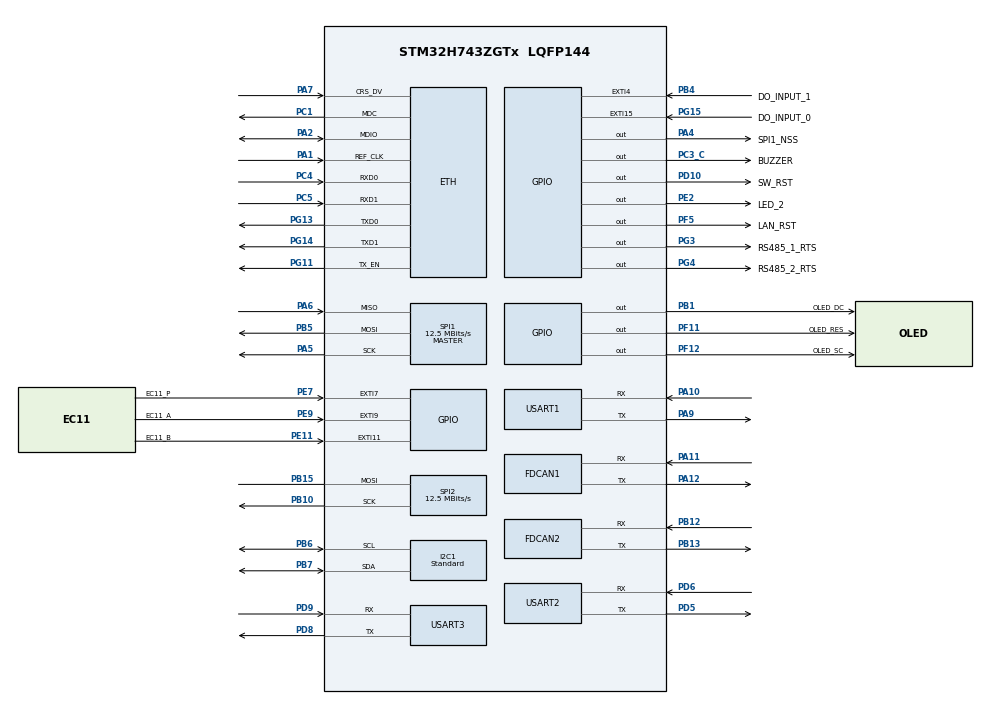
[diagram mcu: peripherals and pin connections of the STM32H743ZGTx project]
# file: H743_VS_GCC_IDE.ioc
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CORTEX_M7.AccessPermission_S-Cortex_Memory_Protection_Unit_Region1_Settings_S=MPU_REGION_FULL_ACCESS
CORTEX_M7.AccessPermission_S-Cortex_Memory_Protection_Unit_Region2_Settings_S=MPU_REGION_FULL_ACCESS
CORTEX_M7.AccessPermission_S-Cortex_Memory_Protection_Unit_Region3_Settings_S=MPU_REGION_FULL_ACCESS
CORTEX_M7.AccessPermission_S-Cortex_Memory_Protection_Unit_Region4_Settings_S=MPU_REGION_FULL_ACCESS
CORTEX_M7.AccessPermission_Spec=MPU_REGION_FULL_ACCESS
CORTEX_M7.BaseAddress_S-Cortex_Memory_Protection_Unit_Region1_Settings_S=0x30000000
CORTEX_M7.BaseAddress_S-Cortex_Memory_Protection_Unit_Region2_Settings_S=0x30004000
CORTEX_M7.BaseAddress_S-Cortex_Memory_Protection_Unit_Region3_Settings_S=0x38000000
CORTEX_M7.BaseAddress_S-Cortex_Memory_Protection_Unit_Region4_Settings_S=0x38800000
CORTEX_M7.BaseAddress_Spec=0x24000000
CORTEX_M7.CPU_DCache=Enabled
CORTEX_M7.CPU_ICache=Enabled
CORTEX_M7.DisableExec_S-Cortex_Memory_Protection_Unit_Region1_Settings_S=MPU_INSTRUCTION_ACCESS_DISABLE
CORTEX_M7.DisableExec_S-Cortex_Memory_Protection_Unit_Region2_Settings_S=MPU_INSTRUCTION_ACCESS_DISABLE
CORTEX_M7.DisableExec_S-Cortex_Memory_Protection_Unit_Region3_Settings_S=MPU_INSTRUCTION_ACCESS_DISABLE
CORTEX_M7.DisableExec_S-Cortex_Memory_Protection_Unit_Region4_Settings_S=MPU_INSTRUCTION_ACCESS_DISABLE
CORTEX_M7.DisableExec_Spec=MPU_INSTRUCTION_ACCESS_DISABLE
CORTEX_M7.Enable_S-Cortex_Memory_Protection_Unit_Region1_Settings_S=MPU_REGION_ENABLE
CORTEX_M7.Enable_S-Cortex_Memory_Protection_Unit_Region2_Settings_S=MPU_REGION_ENABLE
CORTEX_M7.Enable_S-Cortex_Memory_Protection_Unit_Region3_Settings_S=MPU_REGION_ENABLE
CORTEX_M7.Enable_S-Cortex_Memory_Protection_Unit_Region4_Settings_S=MPU_REGION_ENABLE
CORTEX_M7.Enable_S-Cortex_Memory_Protection_Unit_Region5_Settings_S=__NULL
CORTEX_M7.IsBufferable_S-Cortex_Memory_Protection_Unit_Region1_Settings_S=MPU_ACCESS_BUFFERABLE
CORTEX_M7.IsBufferable_S-Cortex_Memory_Protection_Unit_Region2_Settings_S=MPU_ACCESS_BUFFERABLE
CORTEX_M7.IsBufferable_S-Cortex_Memory_Protection_Unit_Region3_Settings_S=MPU_ACCESS_BUFFERABLE
CORTEX_M7.IsBufferable_S-Cortex_Memory_Protection_Unit_Region4_Settings_S=MPU_ACCESS_NOT_BUFFERABLE
CORTEX_M7.IsBufferable_Spec=MPU_ACCESS_NOT_BUFFERABLE
CORTEX_M7.IsCacheable_S-Cortex_Memory_Protection_Unit_Region2_Settings_S=MPU_ACCESS_NOT_CACHEABLE
CORTEX_M7.IsCacheable_S-Cortex_Memory_Protection_Unit_Region4_Settings_S=MPU_ACCESS_NOT_CACHEABLE
CORTEX_M7.IsCacheable_Spec=MPU_ACCESS_CACHEABLE
CORTEX_M7.IsShareable_S-Cortex_Memory_Protection_Unit_Region1_Settings_S=MPU_ACCESS_SHAREABLE
CORTEX_M7.IsShareable_S-Cortex_Memory_Protection_Unit_Region2_Settings_S=MPU_ACCESS_SHAREABLE
CORTEX_M7.IsShareable_S-Cortex_Memory_Protection_Unit_Region3_Settings_S=MPU_ACCESS_SHAREABLE
CORTEX_M7.IsShareable_S-Cortex_Memory_Protection_Unit_Region4_Settings_S=MPU_ACCESS_NOT_SHAREABLE
CORTEX_M7.IsShareable_Spec=MPU_ACCESS_NOT_SHAREABLE
CORTEX_M7.Size_S-Cortex_Memory_Protection_Unit_Region1_Settings_S=MPU_REGION_SIZE_256KB
CORTEX_M7.Size_S-Cortex_Memory_Protection_Unit_Region2_Settings_S=MPU_REGION_SIZE_32KB
CORTEX_M7.Size_S-Cortex_Memory_Protection_Unit_Region3_Settings_S=MPU_REGION_SIZE_64KB
CORTEX_M7.Size_S-Cortex_Memory_Protection_Unit_Region4_Settings_S=MPU_REGION_SIZE_4KB
CORTEX_M7.Size_Spec=MPU_REGION_SIZE_512KB
CORTEX_M7.SubRegionDisable_Spec=0x00
CORTEX_M7.TypeExtField_S-Cortex_Memory_Protection_Unit_Region2_Settings_S=MPU_TEX_LEVEL0
CORTEX_M7.default_mode_Activation=1
Dma.I2C1_TX.0.Direction=DMA_MEMORY_TO_PERIPH
Dma.I2C1_TX.0.EventEnable=DISABLE
Dma.I2C1_TX.0.FIFOMode=DMA_FIFOMODE_DISABLE
Dma.I2C1_TX.0.Instance=DMA1_Stream3
Dma.I2C1_TX.0.MemDataAlignment=DMA_MDATAALIGN_BYTE
Dma.I2C1_TX.0.MemInc=DMA_MINC_ENABLE
Dma.I2C1_TX.0.Mode=DMA_NORMAL
Dma.I2C1_TX.0.PeriphDataAlignment=DMA_PDATAALIGN_BYTE
Dma.I2C1_TX.0.PeriphInc=DMA_PINC_DISABLE
Dma.I2C1_TX.0.Polarity=HAL_DMAMUX_REQ_GEN_RISING
Dma.I2C1_TX.0.Priority=DMA_PRIORITY_LOW
Dma.I2C1_TX.0.RequestNumber=1
Dma.I2C1_TX.0.SignalID=NONE
Dma.I2C1_TX.0.SyncEnable=DISABLE
Dma.I2C1_TX.0.SyncPolarity=HAL_DMAMUX_SYNC_NO_EVENT
Dma.I2C1_TX.0.SyncRequestNumber=1
Dma.I2C1_TX.0.SyncSignalID=NONE
Dma.Request0=I2C1_TX
Dma.Request1=USART2_RX
Dma.Request2=USART2_TX
Dma.Request3=USART1_RX
Dma.Request4=USART1_TX
Dma.USART1_RX.3.Direction=DMA_PERIPH_TO_MEMORY
Dma.USART1_RX.3.EventEnable=DISABLE
Dma.USART1_RX.3.FIFOMode=DMA_FIFOMODE_DISABLE
Dma.USART1_RX.3.Instance=DMA1_Stream0
Dma.USART1_RX.3.MemDataAlignment=DMA_MDATAALIGN_BYTE
Dma.USART1_RX.3.MemInc=DMA_MINC_ENABLE
Dma.USART1_RX.3.Mode=DMA_NORMAL
Dma.USART1_RX.3.PeriphDataAlignment=DMA_PDATAALIGN_BYTE
Dma.USART1_RX.3.PeriphInc=DMA_PINC_DISABLE
Dma.USART1_RX.3.Polarity=HAL_DMAMUX_REQ_GEN_RISING
Dma.USART1_RX.3.Priority=DMA_PRIORITY_HIGH
Dma.USART1_RX.3.RequestNumber=1
Dma.USART1_RX.3.SignalID=NONE
Dma.USART1_RX.3.SyncEnable=DISABLE
Dma.USART1_RX.3.SyncPolarity=HAL_DMAMUX_SYNC_NO_EVENT
Dma.USART1_RX.3.SyncRequestNumber=1
Dma.USART1_RX.3.SyncSignalID=NONE
Dma.USART1_TX.4.Direction=DMA_MEMORY_TO_PERIPH
Dma.USART1_TX.4.EventEnable=DISABLE
Dma.USART1_TX.4.FIFOMode=DMA_FIFOMODE_DISABLE
Dma.USART1_TX.4.Instance=DMA1_Stream1
Dma.USART1_TX.4.MemDataAlignment=DMA_MDATAALIGN_BYTE
Dma.USART1_TX.4.MemInc=DMA_MINC_ENABLE
Dma.USART1_TX.4.Mode=DMA_NORMAL
Dma.USART1_TX.4.PeriphDataAlignment=DMA_PDATAALIGN_BYTE
Dma.USART1_TX.4.PeriphInc=DMA_PINC_DISABLE
Dma.USART1_TX.4.Polarity=HAL_DMAMUX_REQ_GEN_RISING
Dma.USART1_TX.4.Priority=DMA_PRIORITY_HIGH
Dma.USART1_TX.4.RequestNumber=1
Dma.USART1_TX.4.SignalID=NONE
Dma.USART1_TX.4.SyncEnable=DISABLE
Dma.USART1_TX.4.SyncPolarity=HAL_DMAMUX_SYNC_NO_EVENT
Dma.USART1_TX.4.SyncRequestNumber=1
Dma.USART1_TX.4.SyncSignalID=NONE
Dma.USART2_RX.1.Direction=DMA_PERIPH_TO_MEMORY
Dma.USART2_RX.1.EventEnable=DISABLE
Dma.USART2_RX.1.FIFOMode=DMA_FIFOMODE_DISABLE
Dma.USART2_RX.1.Instance=DMA1_Stream4
Dma.USART2_RX.1.MemDataAlignment=DMA_MDATAALIGN_BYTE
Dma.USART2_RX.1.MemInc=DMA_MINC_ENABLE
Dma.USART2_RX.1.Mode=DMA_NORMAL
Dma.USART2_RX.1.PeriphDataAlignment=DMA_PDATAALIGN_BYTE
Dma.USART2_RX.1.PeriphInc=DMA_PINC_DISABLE
Dma.USART2_RX.1.Polarity=HAL_DMAMUX_REQ_GEN_RISING
Dma.USART2_RX.1.Priority=DMA_PRIORITY_LOW
Dma.USART2_RX.1.RequestNumber=1
Dma.USART2_RX.1.SignalID=NONE
Dma.USART2_RX.1.SyncEnable=DISABLE
Dma.USART2_RX.1.SyncPolarity=HAL_DMAMUX_SYNC_NO_EVENT
Dma.USART2_RX.1.SyncRequestNumber=1
Dma.USART2_RX.1.SyncSignalID=NONE
Dma.USART2_TX.2.Direction=DMA_MEMORY_TO_PERIPH
Dma.USART2_TX.2.EventEnable=DISABLE
Dma.USART2_TX.2.FIFOMode=DMA_FIFOMODE_DISABLE
Dma.USART2_TX.2.Instance=DMA1_Stream5
Dma.USART2_TX.2.MemDataAlignment=DMA_MDATAALIGN_BYTE
Dma.USART2_TX.2.MemInc=DMA_MINC_ENABLE
Dma.USART2_TX.2.Mode=DMA_NORMAL
Dma.USART2_TX.2.PeriphDataAlignment=DMA_PDATAALIGN_BYTE
Dma.USART2_TX.2.PeriphInc=DMA_PINC_DISABLE
Dma.USART2_TX.2.Polarity=HAL_DMAMUX_REQ_GEN_RISING
Dma.USART2_TX.2.Priority=DMA_PRIORITY_LOW
Dma.USART2_TX.2.RequestNumber=1
Dma.USART2_TX.2.SignalID=NONE
Dma.USART2_TX.2.SyncEnable=DISABLE
Dma.USART2_TX.2.SyncPolarity=HAL_DMAMUX_SYNC_NO_EVENT
Dma.USART2_TX.2.SyncRequestNumber=1
Dma.USART2_TX.2.SyncSignalID=NONE
ETH.ETH_RX_DESC_CNT=4
ETH.ETH_TX_DESC_CNT=4
ETH.MediaInterface=HAL_ETH_RMII_MODE
ETH.RxBuffLen=1536
ETH.RxBufferAddress=0x30000200
ETH.RxDescAddress=0x30000000
ETH.TxDescAddress=0x30000100
FDCAN1.CalculateBaudRateNominal=500000
FDCAN1.CalculateTimeBitNominal=2000
FDCAN1.CalculateTimeQuantumNominal=50.0
FDCAN1.DataPrescaler=5
FDCAN1.DataTimeSeg1=31
FDCAN1.DataTimeSeg2=8
FDCAN1.NominalPrescaler=5
FDCAN1.NominalTimeSeg1=31
FDCAN1.NominalTimeSeg2=8
FDCAN1.RxFifo0ElmtsNbr=32
FDCAN1.StdFiltersNbr=1
FDCAN1.TxFifoQueueElmtsNbr=16
FDCAN2.CalculateBaudRateNominal=500000
FDCAN2.CalculateTimeBitNominal=2000
FDCAN2.CalculateTimeQuantumNominal=50.0
FDCAN2.DataPrescaler=5
FDCAN2.DataTimeSeg1=31
FDCAN2.DataTimeSeg2=8
FDCAN2.MessageRAMOffset=0x406
FDCAN2.NominalPrescaler=5
FDCAN2.NominalTimeSeg1=31
FDCAN2.NominalTimeSeg2=8
FDCAN2.RxFifo1ElmtsNbr=32
FDCAN2.StdFiltersNbr=1
FDCAN2.TxFifoQueueElmtsNbr=32
FREERTOS.HEAP_NUMBER=4
FREERTOS.Tasks01=defaultTask,24,4096,StartDefaultTask,Default,NULL,Dynamic,NULL,NULL
FREERTOS.configENABLE_FPU=1
FREERTOS.configMINIMAL_STACK_SIZE=1024
FREERTOS.configTIMER_QUEUE_LENGTH=20
FREERTOS.configTIMER_TASK_PRIORITY=24
FREERTOS.configTIMER_TASK_STACK_DEPTH=20480
FREERTOS.configTOTAL_HEAP_SIZE=200*1024
FREERTOS.configUSE_NEWLIB_REENTRANT=1
FREERTOS.configUSE_TICKLESS_IDLE=1
I2C1.CustomTiming=Disabled
I2C1.I2C_Coeff_DF=10
I2C1.I2C_Fall_Time=20
I2C1.I2C_Rise_Time=20
I2C1.I2C_Speed_Mode=I2C_Standard
I2C1.Timing=0x10D0E0FF
IWDG1.Prescaler=IWDG_PRESCALER_4
LWIP.BSP.number=1
LWIP.DEFAULT_THREAD_PRIO=28
LWIP.ETH_RX_BUFFER_CNT=128
LWIP.IP_ADDRESS=000.000.000.000
LWIP.LWIP_ALLOW_MEM_FREE_FROM_OTHER_CONTEXT=1
LWIP.LWIP_DHCP=0
LWIP.LWIP_NETCONN_FULLDUPLEX=1
LWIP.LWIP_RAM_HEAP_POINTER=0x30000800
LWIP.LWIP_SNTP=1
LWIP.LWIP_TFTP=1
LWIP.MEMP_MEM_INIT=1
LWIP.MEMP_MEM_MALLOC=1
LWIP.MEMP_NUM_PBUF=64
LWIP.MEMP_USE_CUSTOM_POOLS=1
LWIP.MEM_LIBC_MALLOC=1
LWIP.MEM_SIZE=65535
LWIP.NETMASK_ADDRESS=000.000.000.000
LWIP.PBUF_POOL_SIZE=128
LWIP.SLIPIF_THREAD_PRIO=28
LWIP.TCPIP_THREAD_PRIO=32
LWIP.TCPIP_THREAD_STACKSIZE=4096
LWIP.TCP_SND_QUEUELEN=24
LWIP.Version=v2.1.2_Cube
LWIP0.BSP.STBoard=false
LWIP0.BSP.api=BSP_COMPONENT_DRIVER
LWIP0.BSP.component=LAN8742
LWIP0.BSP.instance=LAN8742
LWIP0.BSP.name=Driver_PHY
LWIP0.BSP.semaphore=S_LAN8742
LWIP0.BSP.solution=LAN8742
Mcu.Family=STM32H7
Mcu.Name=STM32H743ZGTx
Mcu.Package=LQFP144
NVIC.DMA1_Stream0_IRQn=true\:5\:0\:false\:false\:true\:true\:false\:true\:true
NVIC.DMA1_Stream1_IRQn=true\:5\:0\:false\:false\:true\:true\:false\:true\:true
NVIC.DMA1_Stream3_IRQn=true\:5\:0\:false\:false\:true\:true\:false\:true\:true
NVIC.DMA1_Stream4_IRQn=true\:5\:0\:false\:false\:true\:true\:false\:true\:true
NVIC.DMA1_Stream5_IRQn=true\:5\:0\:false\:false\:true\:true\:false\:true\:true
NVIC.ETH_IRQn=true\:5\:0\:true\:false\:true\:true\:true\:true\:true
NVIC.EXTI15_10_IRQn=true\:6\:0\:true\:false\:true\:true\:true\:true\:true
NVIC.EXTI4_IRQn=true\:6\:0\:true\:false\:true\:true\:true\:true\:true
NVIC.EXTI9_5_IRQn=true\:6\:0\:true\:false\:true\:false\:true\:true\:true
NVIC.FDCAN1_IT0_IRQn=true\:5\:0\:false\:false\:true\:true\:true\:true\:true
NVIC.FDCAN2_IT0_IRQn=true\:5\:0\:false\:false\:true\:true\:true\:true\:true
NVIC.PriorityGroup=NVIC_PRIORITYGROUP_4
NVIC.TIM2_IRQn=true\:5\:0\:false\:false\:false\:true\:true\:true\:true
NVIC.TIM7_IRQn=true\:15\:0\:false\:false\:true\:false\:false\:true\:true
NVIC.TimeBase=TIM7_IRQn
NVIC.TimeBaseIP=TIM7
NVIC.USART1_IRQn=true\:7\:0\:true\:false\:false\:true\:true\:true\:true
NVIC.USART2_IRQn=true\:5\:0\:true\:false\:true\:true\:true\:true\:true
NVIC.USART3_IRQn=true\:5\:0\:true\:false\:false\:true\:true\:true\:true
PA1.GPIO_Mode=GPIO_MODE_AF_PP
PA1.GPIO_PuPd=GPIO_NOPULL
PA1.GPIO_Speed=GPIO_SPEED_FREQ_VERY_HIGH
PA1.Mode=RMII
PA1.Signal=ETH_REF_CLK
PA10.GPIO_PuPd=GPIO_PULLUP
PA10.GPIO_Speed=GPIO_SPEED_FREQ_HIGH
PA10.Mode=Asynchronous
PA10.Signal=USART1_RX
PA11.Mode=FDCAN_Activate
PA11.Signal=FDCAN1_RX
PA12.Mode=FDCAN_Activate
PA12.Signal=FDCAN1_TX
PA13\ (JTMS/SWDIO).Mode=Serial_Wire
PA13\ (JTMS/SWDIO).Signal=DEBUG_JTMS-SWDIO
PA14\ (JTCK/SWCLK).Mode=Serial_Wire
PA14\ (JTCK/SWCLK).Signal=DEBUG_JTCK-SWCLK
PA2.GPIO_Mode=GPIO_MODE_AF_PP
PA2.GPIO_PuPd=GPIO_NOPULL
PA2.GPIO_Speed=GPIO_SPEED_FREQ_VERY_HIGH
PA2.Mode=RMII
PA2.Signal=ETH_MDIO
PA4.GPIO_Label=SPI1_NSS
PA4.GPIO_Speed=GPIO_SPEED_FREQ_MEDIUM
PA4.Signal=GPIO_Output
PA5.GPIO_Speed=GPIO_SPEED_FREQ_VERY_HIGH
PA5.Mode=Full_Duplex_Master
PA5.Signal=SPI1_SCK
PA6.GPIO_Speed=GPIO_SPEED_FREQ_VERY_HIGH
PA6.Mode=Full_Duplex_Master
PA6.Signal=SPI1_MISO
PA7.GPIO_Mode=GPIO_MODE_AF_PP
PA7.GPIO_PuPd=GPIO_NOPULL
PA7.GPIO_Speed=GPIO_SPEED_FREQ_VERY_HIGH
PA7.Mode=RMII
PA7.Signal=ETH_CRS_DV
PA9.GPIO_PuPd=GPIO_PULLUP
PA9.GPIO_Speed=GPIO_SPEED_FREQ_HIGH
PA9.Mode=Asynchronous
PA9.Signal=USART1_TX
PB1.GPIO_Label=OLED_DC
PB1.Signal=GPIO_Output
PB10.Mode=Simplex_Bidirectional_Master
PB10.Signal=SPI2_SCK
PB12.Mode=FDCAN_Activate
PB12.Signal=FDCAN2_RX
PB13.Mode=FDCAN_Activate
PB13.Signal=FDCAN2_TX
PB15.Mode=Simplex_Bidirectional_Master
PB15.Signal=SPI2_MOSI
PB4\ (NJTRST).GPIO_Label=DO_INPUT_1
PB4\ (NJTRST).Signal=GPXTI4
PB5.GPIO_Speed=GPIO_SPEED_FREQ_VERY_HIGH
PB5.Mode=Full_Duplex_Master
PB5.Signal=SPI1_MOSI
PB6.GPIO_Pu=GPIO_PULLUP
PB6.GPIO_Speed=GPIO_SPEED_FREQ_HIGH
PB6.Mode=I2C
PB6.Signal=I2C1_SCL
PB7.GPIO_Pu=GPIO_PULLUP
PB7.GPIO_Speed=GPIO_SPEED_FREQ_HIGH
PB7.Mode=I2C
PB7.Signal=I2C1_SDA
PC1.GPIO_Mode=GPIO_MODE_AF_PP
PC1.GPIO_PuPd=GPIO_NOPULL
PC1.GPIO_Speed=GPIO_SPEED_FREQ_VERY_HIGH
PC1.Mode=RMII
PC1.Signal=ETH_MDC
PC3_C.GPIO_Label=BUZZER
PC3_C.GPIO_Speed=GPIO_SPEED_FREQ_HIGH
PC3_C.Signal=GPIO_Output
PC4.GPIO_Mode=GPIO_MODE_AF_PP
PC4.GPIO_PuPd=GPIO_NOPULL
PC4.GPIO_Speed=GPIO_SPEED_FREQ_VERY_HIGH
PC4.Mode=RMII
PC4.Signal=ETH_RXD0
PC5.GPIO_Mode=GPIO_MODE_AF_PP
PC5.GPIO_PuPd=GPIO_NOPULL
PC5.GPIO_Speed=GPIO_SPEED_FREQ_VERY_HIGH
PC5.Mode=RMII
PC5.Signal=ETH_RXD1
PD10.GPIO_Label=SW_RST
PD10.Signal=GPIO_Output
PD5.GPIO_PuPd=GPIO_PULLUP
PD5.GPIO_Speed=GPIO_SPEED_FREQ_HIGH
PD5.Mode=Asynchronous
PD5.Signal=USART2_TX
PD6.GPIO_PuPd=GPIO_PULLUP
PD6.GPIO_Speed=GPIO_SPEED_FREQ_HIGH
PD6.Mode=Asynchronous
PD6.Signal=USART2_RX
PD8.GPIO_PuPd=GPIO_PULLUP
PD8.GPIO_Speed=GPIO_SPEED_FREQ_HIGH
PD8.Mode=Asynchronous
PD8.Signal=USART3_TX
PD9.GPIO_PuPd=GPIO_PULLUP
PD9.GPIO_Speed=GPIO_SPEED_FREQ_HIGH
PD9.Mode=Asynchronous
PD9.Signal=USART3_RX
PE11.GPIO_Label=EC11_B
PE11.Signal=GPXTI11
PE2.GPIO_Label=LED_2
PE2.GPIO_PuPd=GPIO_PULLUP
PE2.Signal=GPIO_Output
PE7.GPIO_Label=EC11_P
PE7.GPIO_ModeDefaultEXTI=GPIO_MODE_IT_RISING_FALLING
PE7.Signal=GPXTI7
PE9.GPIO_Label=EC11_A
PE9.Signal=GPXTI9
PF11.GPIO_Label=OLED_RES
PF11.Signal=GPIO_Output
PF12.GPIO_Label=OLED_SC
PF12.Signal=GPIO_Output
PF5.GPIO_Label=LAN_RST
PF5.GPIO_PuPd=GPIO_NOPULL
PF5.PinState=GPIO_PIN_SET
PF5.Signal=GPIO_Output
PG11.GPIO_Mode=GPIO_MODE_AF_PP
PG11.GPIO_PuPd=GPIO_NOPULL
PG11.GPIO_Speed=GPIO_SPEED_FREQ_VERY_HIGH
PG11.Mode=RMII
PG11.Signal=ETH_TX_EN
PG13.GPIO_Mode=GPIO_MODE_AF_PP
PG13.GPIO_PuPd=GPIO_NOPULL
PG13.GPIO_Speed=GPIO_SPEED_FREQ_VERY_HIGH
PG13.Mode=RMII
PG13.Signal=ETH_TXD0
PG14.GPIO_Mode=GPIO_MODE_AF_PP
PG14.GPIO_PuPd=GPIO_NOPULL
PG14.GPIO_Speed=GPIO_SPEED_FREQ_VERY_HIGH
PG14.Mode=RMII
PG14.Signal=ETH_TXD1
PG15.GPIO_Label=DO_INPUT_0
PG15.GPIO_PuPd=GPIO_PULLDOWN
PG15.Signal=GPXTI15
PG3.GPIO_Label=RS485_1_RTS
PG3.GPIO_ModeDefaultOutputPP=GPIO_MODE_OUTPUT_PP
PG3.GPIO_PuPd=GPIO_NOPULL
PG3.GPIO_Speed=GPIO_SPEED_FREQ_MEDIUM
PG3.PinState=GPIO_PIN_RESET
PG3.Signal=GPIO_Output
PG4.GPIO_Label=RS485_2_RTS
PG4.GPIO_PuPd=GPIO_NOPULL
PG4.GPIO_Speed=GPIO_SPEED_FREQ_MEDIUM
PG4.PinState=GPIO_PIN_RESET
PG4.Signal=GPIO_Output
PH0-OSC_IN\ (PH0).Mode=HSE-External-Oscillator
PH0-OSC_IN\ (PH0).Signal=RCC_OSC_IN
PH1-OSC_OUT\ (PH1).Mode=HSE-External-Oscillator
PH1-OSC_OUT\ (PH1).Signal=RCC_OSC_OUT
ProjectManager.HeapSize=0x1200
ProjectManager.StackSize=0x1000
ProjectManager.TargetToolchain=CMake
RCC.ADCFreq_Value=100000000
RCC.APB1Freq_Value=120000000
RCC.APB2Freq_Value=120000000
RCC.APB3Freq_Value=120000000
RCC.APB4Freq_Value=120000000
RCC.CortexFreq_Value=480000000
RCC.D1PPRE=RCC_APB3_DIV2
RCC.D2PPRE1=RCC_APB1_DIV2
RCC.D2PPRE2=RCC_APB2_DIV2
RCC.D3PPRE=RCC_APB4_DIV2
RCC.DIVM1=5
RCC.DIVM2=5
RCC.DIVM3=5
RCC.DIVN1=192
RCC.DIVN2=160
RCC.DIVN3=160
RCC.DIVP2=8
RCC.DIVP3=4
RCC.DIVQ2=8
RCC.DIVR3=8
RCC.FDCANCLockSelection=RCC_FDCANCLKSOURCE_PLL2
RCC.HCLKFreq_Value=240000000
RCC.HPRE=RCC_HCLK_DIV2
RCC.I2C123CLockSelection=RCC_I2C123CLKSOURCE_PLL3
RCC.PLLSourceVirtual=RCC_PLLSOURCE_HSE
RCC.SPI123CLockSelection=RCC_SPI123CLKSOURCE_PLL3
RCC.SYSCLKFreq_VALUE=480000000
RCC.SYSCLKSource=RCC_SYSCLKSOURCE_PLLCLK
RCC.USBFreq_Value=480000000
RTC.Format=RTC_FORMAT_BCD
RTC.Year=25
SPI1.BaudRatePrescaler=SPI_BAUDRATEPRESCALER_16
SPI1.CLKPhase=SPI_PHASE_1EDGE
SPI1.CLKPolarity=SPI_POLARITY_LOW
SPI1.CalculateBaudRate=12.5 MBits/s
SPI1.DataSize=SPI_DATASIZE_8BIT
SPI1.Direction=SPI_DIRECTION_2LINES
SPI1.FirstBit=SPI_FIRSTBIT_MSB
SPI1.Mode=SPI_MODE_MASTER
SPI1.VirtualType=VM_MASTER
SPI2.BaudRatePrescaler=SPI_BAUDRATEPRESCALER_16
SPI2.CLKPhase=SPI_PHASE_2EDGE
SPI2.CLKPolarity=SPI_POLARITY_HIGH
SPI2.CalculateBaudRate=12.5 MBits/s
SPI2.DataSize=SPI_DATASIZE_8BIT
SPI2.Direction=SPI_DIRECTION_1LINE
SPI2.Mode=SPI_MODE_MASTER
SPI2.VirtualType=VM_MASTER
TIM2.AutoReloadPreload=TIM_AUTORELOAD_PRELOAD_DISABLE
TIM2.Prescaler=239
USART1.VirtualMode-Asynchronous=VM_ASYNC
USART2.VirtualMode-Asynchronous=VM_ASYNC
USART3.VirtualMode-Asynchronous=VM_ASYNC
VP_FREERTOS_VS_CMSIS_V2.Mode=CMSIS_V2
VP_IWDG1_VS_IWDG.Mode=IWDG_Activate
VP_LWIP_VS_Enabled.Mode=Enabled
VP_MEMORYMAP_VS_MEMORYMAP.Mode=CurAppReg
VP_RTC_VS_RTC_Activate.Mode=RTC_Enabled
VP_RTC_VS_RTC_Calendar.Mode=RTC_Calendar
VP_SYS_VS_tim7.Mode=TIM7
VP_TIM2_VS_ClockSourceINT.Mode=Internal
board=custom

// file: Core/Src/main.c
/* USER CODE BEGIN Header */
/**
  ******************************************************************************
  * @file           : main.c
  * @brief          : Main program body
  ******************************************************************************
  * @attention
  *
  * Copyright (c) 2026 STMicroelectronics.
  * All rights reserved.
  *
  * This software is licensed under terms that can be found in the LICENSE file
  * in the root directory of this software component.
  * If no LICENSE file comes with this software, it is provided AS-IS.
  *
  ******************************************************************************
  */
/* USER CODE END Header */
#include "main.h"
#include "cmsis_os.h"
#include "dma.h"
#include "fdcan.h"
#include "i2c.h"
#include "iwdg.h"
#include "lwip.h"
#include "rtc.h"
#include "spi.h"
#include "tim.h"
#include "usart.h"
#include "gpio.h"

/* USER CODE BEGIN Includes */
#include "cJSON.h"
/* USER CODE END Includes */

void SystemClock_Config(void);
void PeriphCommonClock_Config(void);
static void MPU_Config(void);
void MX_FREERTOS_Init(void);

int main(void)
{

  /* USER CODE BEGIN 1 */
  /* App 运行在内部 Flash 第二 bank（0x08100000），需将向量表偏移指向此处，
     否则中断仍会跳到 Bootloader 区（0x08000000）导致 HardFault。 */
  SCB->VTOR = 0x08100000UL;
  /* USER CODE END 1 */

  /* MPU Configuration--------------------------------------------------------*/
  MPU_Config();

  /* Enable the CPU Cache */

  /* Enable I-Cache---------------------------------------------------------*/
  SCB_EnableICache();

  /* Enable D-Cache---------------------------------------------------------*/
  SCB_EnableDCache();

  /* MCU Configuration--------------------------------------------------------*/

  /* Reset of all peripherals, Initializes the Flash interface and the Systick. */
  HAL_Init();

  /* USER CODE BEGIN Init */
  //HAL_Delay(500);
  /* USER CODE END Init */

  /* Configure the system clock */
  SystemClock_Config();

  /* Configure the peripherals common clocks */
  PeriphCommonClock_Config();

  /* Initialize all configured peripherals */
  MX_GPIO_Init();
  MX_DMA_Init();
  MX_FDCAN1_Init();
  MX_FDCAN2_Init();
  MX_I2C1_Init();
  MX_RTC_Init();
  MX_SPI1_Init();
  MX_USART1_UART_Init();
  MX_USART3_UART_Init();
  MX_USART2_UART_Init();
  MX_SPI2_Init();
  MX_TIM2_Init();
  MX_IWDG1_Init();
  /* USER CODE BEGIN 2 */
  cJSON_Init_FreeRTOS_Heap();
  /* USER CODE END 2 */

  /* Init scheduler */
  osKernelInitialize();  /* Call init function for freertos objects (in cmsis_os2.c) */
  MX_FREERTOS_Init();

  /* Start scheduler */
  osKernelStart();

  /* We should never get here as control is now taken by the scheduler */

  /* Infinite loop */
  while (1)
  {

  }
}

void SystemClock_Config(void)
{
  RCC_OscInitTypeDef RCC_OscInitStruct = {0};
  RCC_ClkInitTypeDef RCC_ClkInitStruct = {0};

  /** Supply configuration update enable
  */
  HAL_PWREx_ConfigSupply(PWR_LDO_SUPPLY);

  /** Configure the main internal regulator output voltage
  */
  __HAL_PWR_VOLTAGESCALING_CONFIG(PWR_REGULATOR_VOLTAGE_SCALE0);

  while(!__HAL_PWR_GET_FLAG(PWR_FLAG_VOSRDY)) {}

  /** Initializes the RCC Oscillators according to the specified parameters
  * in the RCC_OscInitTypeDef structure.
  */
  RCC_OscInitStruct.OscillatorType = RCC_OSCILLATORTYPE_LSI|RCC_OSCILLATORTYPE_HSE;
  RCC_OscInitStruct.HSEState = RCC_HSE_ON;
  RCC_OscInitStruct.LSIState = RCC_LSI_ON;
  RCC_OscInitStruct.PLL.PLLState = RCC_PLL_ON;
  RCC_OscInitStruct.PLL.PLLSource = RCC_PLLSOURCE_HSE;
  RCC_OscInitStruct.PLL.PLLM = 5;
  RCC_OscInitStruct.PLL.PLLN = 192;
  RCC_OscInitStruct.PLL.PLLP = 2;
  RCC_OscInitStruct.PLL.PLLQ = 2;
  RCC_OscInitStruct.PLL.PLLR = 2;
  RCC_OscInitStruct.PLL.PLLRGE = RCC_PLL1VCIRANGE_2;
  RCC_OscInitStruct.PLL.PLLVCOSEL = RCC_PLL1VCOWIDE;
  RCC_OscInitStruct.PLL.PLLFRACN = 0;
  if (HAL_RCC_OscConfig(&RCC_OscInitStruct) != HAL_OK)
  {
    Error_Handler();
  }

  /** Initializes the CPU, AHB and APB buses clocks
  */
  RCC_ClkInitStruct.ClockType = RCC_CLOCKTYPE_HCLK|RCC_CLOCKTYPE_SYSCLK
                              |RCC_CLOCKTYPE_PCLK1|RCC_CLOCKTYPE_PCLK2
                              |RCC_CLOCKTYPE_D3PCLK1|RCC_CLOCKTYPE_D1PCLK1;
  RCC_ClkInitStruct.SYSCLKSource = RCC_SYSCLKSOURCE_PLLCLK;
  RCC_ClkInitStruct.SYSCLKDivider = RCC_SYSCLK_DIV1;
  RCC_ClkInitStruct.AHBCLKDivider = RCC_HCLK_DIV2;
  RCC_ClkInitStruct.APB3CLKDivider = RCC_APB3_DIV2;
  RCC_ClkInitStruct.APB1CLKDivider = RCC_APB1_DIV2;
  RCC_ClkInitStruct.APB2CLKDivider = RCC_APB2_DIV2;
  RCC_ClkInitStruct.APB4CLKDivider = RCC_APB4_DIV2;

  if (HAL_RCC_ClockConfig(&RCC_ClkInitStruct, FLASH_LATENCY_4) != HAL_OK)
  {
    Error_Handler();
  }
}

void PeriphCommonClock_Config(void)
{
  RCC_PeriphCLKInitTypeDef PeriphClkInitStruct = {0};

  /** Initializes the peripherals clock
  */
  PeriphClkInitStruct.PeriphClockSelection = RCC_PERIPHCLK_I2C1|RCC_PERIPHCLK_SPI2
                              |RCC_PERIPHCLK_SPI1|RCC_PERIPHCLK_FDCAN;
  PeriphClkInitStruct.PLL2.PLL2M = 5;
  PeriphClkInitStruct.PLL2.PLL2N = 160;
  PeriphClkInitStruct.PLL2.PLL2P = 8;
  PeriphClkInitStruct.PLL2.PLL2Q = 8;
  PeriphClkInitStruct.PLL2.PLL2R = 2;
  PeriphClkInitStruct.PLL2.PLL2RGE = RCC_PLL2VCIRANGE_2;
  PeriphClkInitStruct.PLL2.PLL2VCOSEL = RCC_PLL2VCOWIDE;
  PeriphClkInitStruct.PLL2.PLL2FRACN = 0;
  PeriphClkInitStruct.PLL3.PLL3M = 5;
  PeriphClkInitStruct.PLL3.PLL3N = 160;
  PeriphClkInitStruct.PLL3.PLL3P = 4;
  PeriphClkInitStruct.PLL3.PLL3Q = 2;
  PeriphClkInitStruct.PLL3.PLL3R = 8;
  PeriphClkInitStruct.PLL3.PLL3RGE = RCC_PLL3VCIRANGE_2;
  PeriphClkInitStruct.PLL3.PLL3VCOSEL = RCC_PLL3VCOWIDE;
  PeriphClkInitStruct.PLL3.PLL3FRACN = 0;
  PeriphClkInitStruct.Spi123ClockSelection = RCC_SPI123CLKSOURCE_PLL3;
  PeriphClkInitStruct.FdcanClockSelection = RCC_FDCANCLKSOURCE_PLL2;
  PeriphClkInitStruct.I2c123ClockSelection = RCC_I2C123CLKSOURCE_PLL3;
  if (HAL_RCCEx_PeriphCLKConfig(&PeriphClkInitStruct) != HAL_OK)
  {
    Error_Handler();
  }
}

 /* MPU Configuration */

void MPU_Config(void)
{
  MPU_Region_InitTypeDef MPU_InitStruct = {0};

  /* Disables the MPU */
  HAL_MPU_Disable();

  /** Initializes and configures the Region and the memory to be protected
  */
  MPU_InitStruct.Enable = MPU_REGION_ENABLE;
  MPU_InitStruct.Number = MPU_REGION_NUMBER0;
  MPU_InitStruct.BaseAddress = 0x24000000;
  MPU_InitStruct.Size = MPU_REGION_SIZE_512KB;
  MPU_InitStruct.SubRegionDisable = 0x00;
  MPU_InitStruct.TypeExtField = MPU_TEX_LEVEL0;
  MPU_InitStruct.AccessPermission = MPU_REGION_FULL_ACCESS;
  MPU_InitStruct.DisableExec = MPU_INSTRUCTION_ACCESS_DISABLE;
  MPU_InitStruct.IsShareable = MPU_ACCESS_NOT_SHAREABLE;
  MPU_InitStruct.IsCacheable = MPU_ACCESS_CACHEABLE;
  MPU_InitStruct.IsBufferable = MPU_ACCESS_NOT_BUFFERABLE;

  HAL_MPU_ConfigRegion(&MPU_InitStruct);

  /** Initializes and configures the Region and the memory to be protected
  */
  MPU_InitStruct.Number = MPU_REGION_NUMBER1;
  MPU_InitStruct.BaseAddress = 0x30000000;
  MPU_InitStruct.Size = MPU_REGION_SIZE_256KB;
  MPU_InitStruct.SubRegionDisable = 0x0;
  MPU_InitStruct.IsShareable = MPU_ACCESS_SHAREABLE;
  MPU_InitStruct.IsCacheable = MPU_ACCESS_NOT_CACHEABLE;
  MPU_InitStruct.IsBufferable = MPU_ACCESS_BUFFERABLE;

  HAL_MPU_ConfigRegion(&MPU_InitStruct);

  /** Initializes and configures the Region and the memory to be protected
  */
  MPU_InitStruct.Number = MPU_REGION_NUMBER2;
  MPU_InitStruct.BaseAddress = 0x30004000;
  MPU_InitStruct.Size = MPU_REGION_SIZE_32KB;

  HAL_MPU_ConfigRegion(&MPU_InitStruct);

  /** Initializes and configures the Region and the memory to be protected
  */
  MPU_InitStruct.Number = MPU_REGION_NUMBER3;
  MPU_InitStruct.BaseAddress = 0x38000000;
  MPU_InitStruct.Size = MPU_REGION_SIZE_64KB;

  HAL_MPU_ConfigRegion(&MPU_InitStruct);

  /** Initializes and configures the Region and the memory to be protected
  */
  MPU_InitStruct.Number = MPU_REGION_NUMBER4;
  MPU_InitStruct.BaseAddress = 0x38800000;
  MPU_InitStruct.Size = MPU_REGION_SIZE_4KB;
  MPU_InitStruct.IsShareable = MPU_ACCESS_NOT_SHAREABLE;
  MPU_InitStruct.IsBufferable = MPU_ACCESS_NOT_BUFFERABLE;

  HAL_MPU_ConfigRegion(&MPU_InitStruct);
  /* Enables the MPU */
  HAL_MPU_Enable(MPU_PRIVILEGED_DEFAULT);

}

void HAL_TIM_PeriodElapsedCallback(TIM_HandleTypeDef *htim)
{
  if (htim->Instance == TIM7)
  {
    HAL_IncTick();
  }
}

void Error_Handler(void)
{
  __disable_irq();
  while (1)
  {
  }
}
